# GD32G5x3 register map
File version: 1.0
CPU: CM33 r2p1, little endian, MPU, FPU, 4 interrupt priority bits
Registers are 32-bit, read-write, reset 0x0 unless marked. A register's access mark holds for its fields unless they carry their own. Offsets are from the block's base; [hi:lo] are bit positions; {n}, {i} and the like mark numbered series; 'fields as' and 'values as' point back to an identical list.

## SYSCFG — System and memory architectur
Base 0x40010000
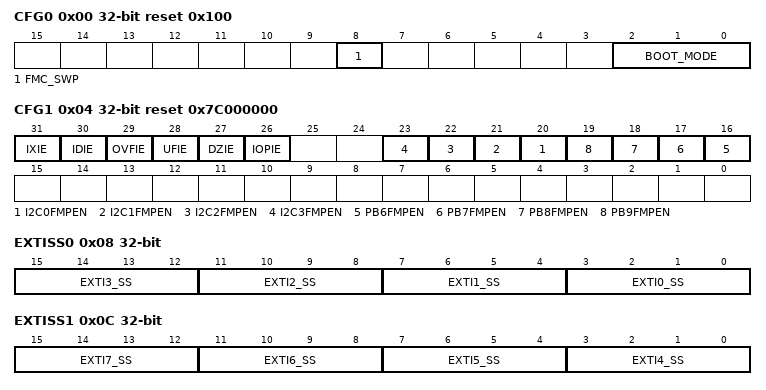
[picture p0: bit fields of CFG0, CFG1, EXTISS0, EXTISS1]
0x00 CFG0 reset 0x100 — System configuration register 0
  [8] FMC_SWP — FMC memory mapping swap
  [2:0] BOOT_MODE
0x04 CFG1 reset 0x7C000000 — System configuration register 1
  [31] IXIE — FPU inexact interrupt enable bit
  [30] IDIE — FPU input denormal interrupt enable bit
  [29] OVFIE — FPU overflow interrupt enable bit
  [28] UFIE — FPU underflow interrupt enable bit
  [27] DZIE — FPU divide by 0 interrupt enable bit
  [26] IOPIE — FPU invalid operation interrupt enable bit
  [n+20] I2C{n}FMPEN (n=0..3) — I2C{n} Fm+ mode enable
  [n+10] PB{n}FMPEN (n=6..9) — I2C Fm+ mode on PB{n} pin enable
0x08 EXTISS0 — EXTI sources selection register 0
  [4n+3:4n] EXTI{n}_SS (n=0..3) — EXTI {n} sources selection
0x0C EXTISS1 — EXTI sources selection register 1
  [4n-13:4n-16] EXTI{n}_SS (n=4..7) — EXTI {n} sources selection
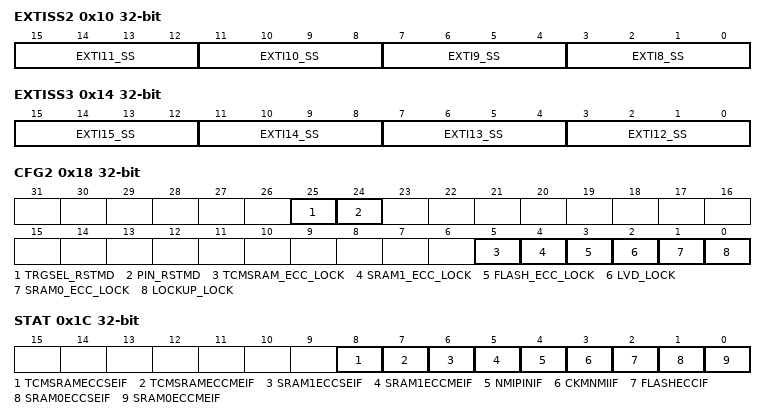
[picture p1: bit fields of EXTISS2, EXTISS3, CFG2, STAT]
0x10 EXTISS2 — EXTI sources selection register 2
  [4n-29:4n-32] EXTI{n}_SS (n=8..11) — EXTI {n} sources selection
0x14 EXTISS3 — EXTI sources selection register 3
  [4n-45:4n-48] EXTI{n}_SS (n=12..15) — EXTI {n} sources selection
0x18 CFG2 — System configuration register 2
  [25] TRGSEL_RSTMD — Trigsel reset mode
  [24] PIN_RSTMD — Pin reset mode
  [5] TCMSRAM_ECC_LOCK — TCMSRAM ECC lock enable bit
  [4] SRAM1_ECC_LOCK — SRAM1 ECC lock enable bit
  [3] FLASH_ECC_LOCK — Flash ECC lockup enable bit
  [2] LVD_LOCK — LVD lcokup enable bit
  [1] SRAM0_ECC_LOCK — SRAM0 ECC lockup enable bit
  [0] LOCKUP_LOCK — Cortex-M33 lockup (Hardfault) output enable bit
0x1C STAT access per field — System status register
  [8] TCMSRAMECCSEIF rw — TCMSRAM single bit correction interrupt flag
  [7] TCMSRAMECCMEIF rw — TCMSRAM multi-bits (two bits) non-correction interrupt flag
  [6] SRAM1ECCSEIF rw — SRAM1 single bit correction interrupt flag
  [5] SRAM1ECCMEIF rw — SRAM1 multi-bits (two bits) non-correction interrupt flag
  [4] NMIPINIF ro — Interrupt flag from NMI pin
  [3] CKMNMIIF rw — HXTAL clock moniotor NMI interrupt flag
  [2] FLASHECCIF rw — Flash ECC NMI interrupt flag
  [1] SRAM0ECCSEIF rw — SRAM0 single bit correction interrupt flag
  [0] SRAM0ECCMEIF rw — SRAM0 multi-bits (two bits) non-correction interrupt flag
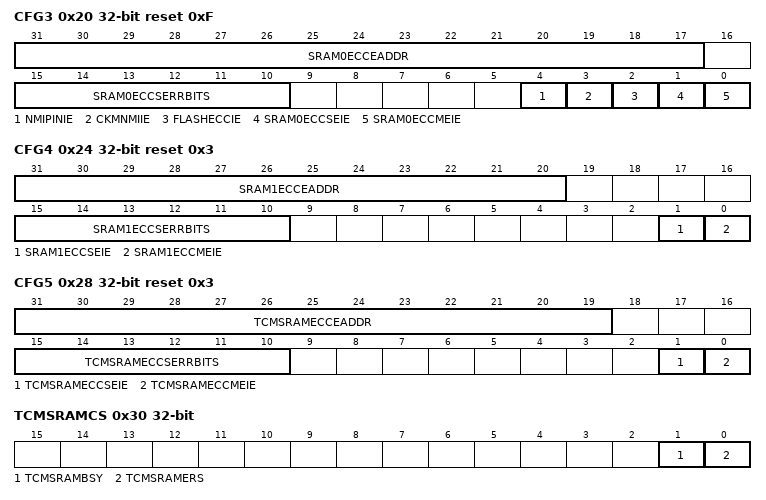
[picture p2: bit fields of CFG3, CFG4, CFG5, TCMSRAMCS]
0x20 CFG3 access per field reset 0xF — System configuration register 3
  [31:17] SRAM0ECCEADDR ro — Record the faulting system address (SRAM0ECCEADDR = SRAM0 address[16:0] >> 2) where the last SRAM0 ECC event on SRAM occurred
  [15:10] SRAM0ECCSERRBITS ro — Which one bit has SRAM0 ECC single-bit correctable error
  [4] NMIPINIE rw — NMI pin interrupt enable
  [3] CKMNMIIE rw — HXTAL clock moniotor NMI interrupt enable
  [2] FLASHECCIE rw — Flash ECC NMI interrupt flag
  [1] SRAM0ECCSEIE rw — SRAM0 single bit correction error interrupt enable
  [0] SRAM0ECCMEIE rw — SRAM0 multi-bits (two bits) non-correction error NMI interrupt enable
0x24 CFG4 access per field reset 0x3 — System configuration register 4
  [31:20] SRAM1ECCEADDR ro — Record the faulting system address (SRAM1ECCEADDR = SRAM1 address[13:0] >> 2) where the last SRAM1 ECC event on SRAM occurred
  [15:10] SRAM1ECCSERRBITS ro — Which one bit has SRAM1 ECC single-bit correctable error
  [1] SRAM1ECCSEIE rw — SRAM1 single bit correction error event flag
  [0] SRAM1ECCMEIE rw — SRAM1 multi-bits (two bits) non-correction error event flag
0x28 CFG5 access per field reset 0x3 — System configuration register 5
  [31:19] TCMSRAMECCEADDR ro — Record the faulting system address (TCMSRAMECCEADDR = TCM SRAM address[14:0] >> 2) where the last TCMSRAM ECC event on SRAM occurred
  [15:10] TCMSRAMECCSERRBITS ro — Which one bit has TCMSRAM ECC single-bit correctable error
  [1] TCMSRAMECCSEIE rw — TCMSRAM single bit correction error event flag
  [0] TCMSRAMECCMEIE rw — TCMSRAM multi-bits (two bits) non-correction error event flag
0x30 TCMSRAMCS access per field — SYSCFG TCMSRAM control and status register
  [1] TCMSRAMBSY ro — TCMSRAM busy flag by erase operation
  [0] TCMSRAMERS rw — TCMSRAM erase
0x34 TCMSRAMKEY wo — SYSCFG TCMSRAM key register
  [7:0] WP_KEY — TCMSRAM write protection key
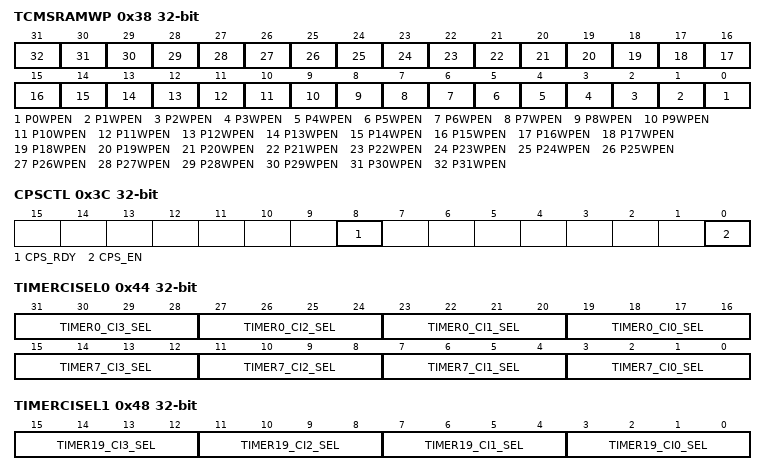
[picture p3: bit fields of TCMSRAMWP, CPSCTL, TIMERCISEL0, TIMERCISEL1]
0x38 TCMSRAMWP — SYSCFG TCMSRAM write protection register
  [n] P{n}WPEN (n=0..31) — TCMSRAM page {n} write protection enable bit
0x3C CPSCTL access per field — I/O Compensation cell control/status register
  [8] CPS_RDY ro — Compensation cell ready flag
  [0] CPS_EN rw — I/O compensation cell enable
0x44 TIMERCISEL0 — Timer input selection register 0
  [4n+19:4n+16] TIMER0_CI{n}_SEL (n=0..3) — Selects TIMER0_CI{n} input
  [4n+3:4n] TIMER7_CI{n}_SEL (n=0..3) — Selects TIMER7_CI{n} input
0x48 TIMERCISEL1 — Timer input selection register 1
  [4n+3:4n] TIMER19_CI{n}_SEL (n=0..3) — Selects TIMER19_CI{n} input
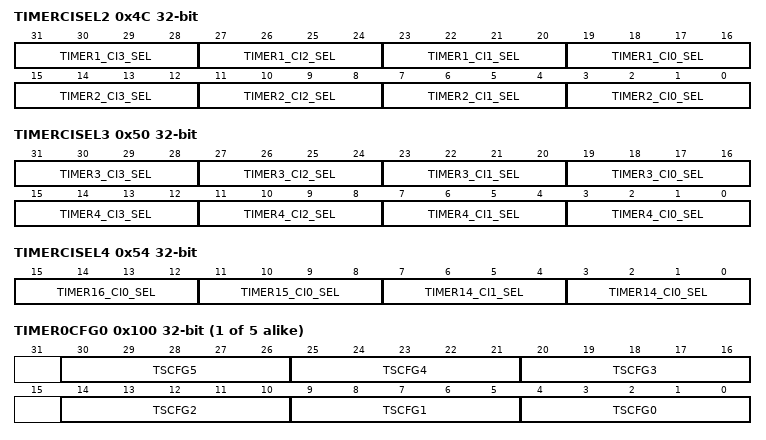
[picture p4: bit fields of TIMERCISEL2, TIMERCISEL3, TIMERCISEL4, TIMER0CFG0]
0x4C TIMERCISEL2 — Timer input selection register 2
  [4n+19:4n+16] TIMER1_CI{n}_SEL (n=0..3) — TIMER1_CI{n} input selection
  [4n+3:4n] TIMER2_CI{n}_SEL (n=0..3) — TIMER2_CI{n} input selection
0x50 TIMERCISEL3 — Timer input selection register 3
  [4n+19:4n+16] TIMER3_CI{n}_SEL (n=0..3) — TIMER3_CI{n} input selection
  [4n+3:4n] TIMER4_CI{n}_SEL (n=0..3) — TIMER4_CI{n} input selection
0x54 TIMERCISEL4 — Timer input selection register 4
  [15:12] TIMER16_CI0_SEL — Selects TIMER16_CI0 input
  [11:8] TIMER15_CI0_SEL — Selects TIMER15_CI0 input
  [7:4] TIMER14_CI1_SEL — Selects TIMER14_CI1 input
  [3:0] TIMER14_CI0_SEL — Selects TIMER14_CI0 input
{0x100+0xC*i} TIMER{i}CFG0 (i=0..4) — TIMER{i} configuration register 0
  [30:26] TSCFG5 — Event mode configuration
  [25:21] TSCFG4 — Pause mode configuration
  [20:16] TSCFG3 — Restart mode configuration
  [14:10] TSCFG2 — Quadrature decoder mode 2 configuration
  [9:5] TSCFG1 — Quadrature decoder mode 1 configuration
  [4:0] TSCFG0 — Quadrature decoder mode 0 configuration
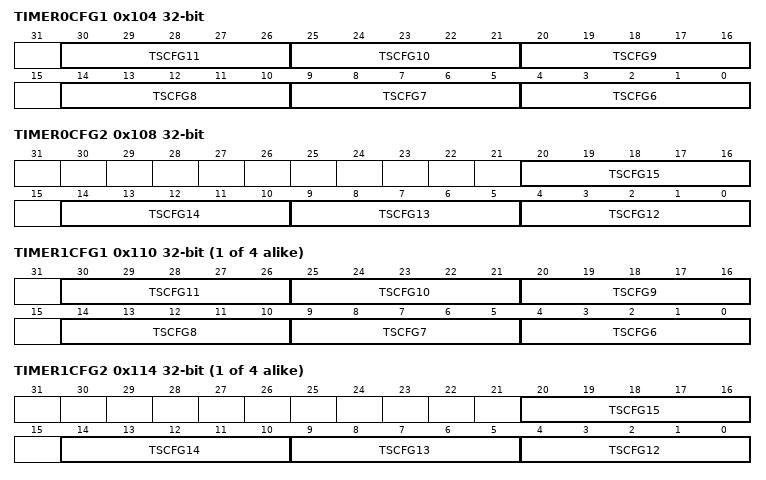
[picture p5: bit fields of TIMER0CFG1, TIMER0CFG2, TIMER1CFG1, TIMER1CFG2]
0x104 TIMER0CFG1 — TIMER1 configuration register 1
  [30:26] TSCFG11 — Decoder mode 2 configuration
  [25:21] TSCFG10 — Decoder mode 1 configuration
  [20:16] TSCFG9 — Decoder mode 0 configuration
  [14:10] TSCFG8 — Pause + restart mode configuration
  [9:5] TSCFG7 — Restart + event mode configuration
  [4:0] TSCFG6 — External clock mode 0 configuration
0x108 TIMER0CFG2 — TIMERx configuration register 2
  [20:16] TSCFG15 — Internal trigger input source configuration
  [14:10] TSCFG14 — Quadrature decoder mode 4 configuration
  [9:5] TSCFG13 — Quadrature decoder mode 3 configuration
  [4:0] TSCFG12 — Decoder mode 3 configuration
{0x104+0xC*i} TIMER{i}CFG1 (i=1..4) — TIMER{i} configuration register 1
  fields as TIMER0CFG1
{0x108+0xC*i} TIMER{i}CFG2 (i=1..4) — TIMER{i} configuration register 2
  fields as TIMER0CFG2
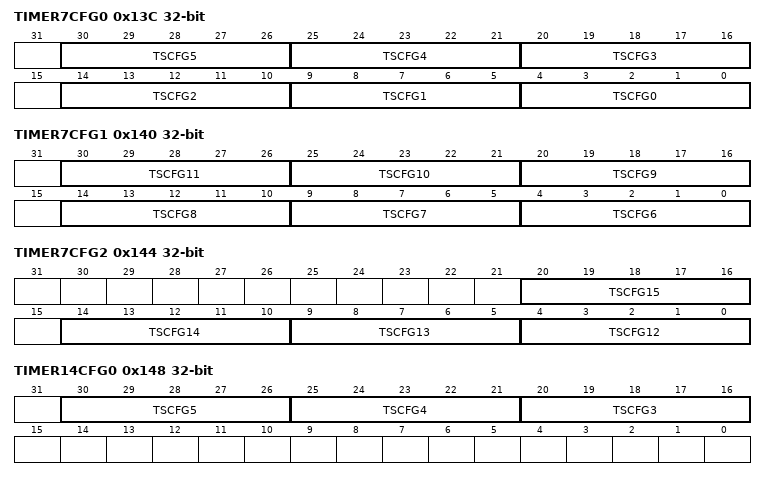
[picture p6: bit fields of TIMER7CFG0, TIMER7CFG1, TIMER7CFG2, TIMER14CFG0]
0x13C TIMER7CFG0 — TIMER7 configuration register 0
  fields as TIMER0CFG0
0x140 TIMER7CFG1 — TIMER7 configuration register 1
  fields as TIMER0CFG1
0x144 TIMER7CFG2 — TIMER7 configuration register 2
  fields as TIMER0CFG2
0x148 TIMER14CFG0 — TIMERx configuration register 0
  [30:26] TSCFG5 — Event mode configuration
  [25:21] TSCFG4 — Pause mode configuration
  [20:16] TSCFG3 — Restart mode configuration
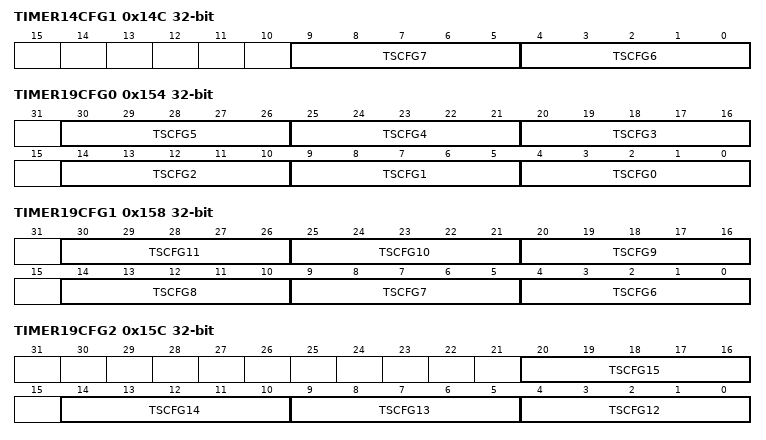
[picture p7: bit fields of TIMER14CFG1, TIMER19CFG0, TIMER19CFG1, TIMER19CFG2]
0x14C TIMER14CFG1 — TIMERx configuration register 1
  [9:5] TSCFG7 — Restart + event mode configuration
  [4:0] TSCFG6 — External clock mode 0 configuration
0x150 TIMER14CFG2 — TIMERx configuration register 2
  [20:16] TSCFG15 — Internal trigger input source configuration
0x154 TIMER19CFG0 — TIMER19 configuration register 0
  fields as TIMER0CFG0
0x158 TIMER19CFG1 — TIMER19 configuration register 1
  fields as TIMER0CFG1
0x15C TIMER19CFG2 — TIMER19 configuration register 2
  fields as TIMER0CFG2
